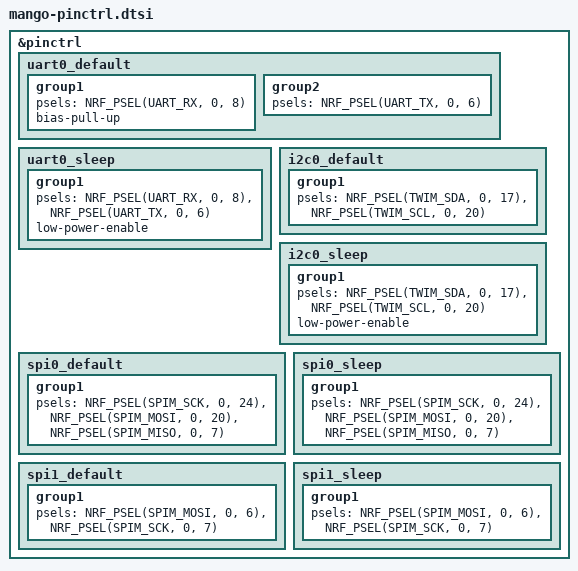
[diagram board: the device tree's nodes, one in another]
&pinctrl {
        uart0_default: uart0_default {
                group1 {
                        psels = <NRF_PSEL(UART_RX, 0, 8)>;
                        bias-pull-up;
                };
                group2 {
                        psels = <NRF_PSEL(UART_TX, 0, 6)>;
                };
        };

        uart0_sleep: uart0_sleep {
                group1 {
                        psels = <NRF_PSEL(UART_RX, 0, 8)>,
                                <NRF_PSEL(UART_TX, 0, 6)>;
                        low-power-enable;
                };
        };

        i2c0_default: i2c0_default {
                group1 {
                        psels = <NRF_PSEL(TWIM_SDA, 0, 17)>,
                                <NRF_PSEL(TWIM_SCL, 0, 20)>;
                };
        };

        i2c0_sleep: i2c0_sleep {
                group1 {
                        psels = <NRF_PSEL(TWIM_SDA, 0, 17)>,
                                <NRF_PSEL(TWIM_SCL, 0, 20)>;
                        low-power-enable;
                };
        };

        spi0_default: spi0_default {
                group1 {
                        psels = <NRF_PSEL(SPIM_SCK, 0, 24)>,
                                <NRF_PSEL(SPIM_MOSI, 0, 20)>,
                                // Unused pin, needed for SPI definition, but not used by the display driver itself.
                                <NRF_PSEL(SPIM_MISO, 0, 7)>; // 0.07 is not broken out on the n!n
                };
        };

        spi0_sleep: spi0_sleep {
                group1 {
                        psels = <NRF_PSEL(SPIM_SCK, 0, 24)>,
                                <NRF_PSEL(SPIM_MOSI, 0, 20)>,
                                // Unused pin, needed for SPI definition, but not used by the display driver itself.
                                <NRF_PSEL(SPIM_MISO, 0, 7)>; // 0.07 is not broken out on the n!n
                };
        };

        // The ws2812 driver only uses MOSI, but the SPIM still needs an SCK pin or the
        // LEDs stay dark. SCK used to be 0.24, which is also the display's SCK on spi0,
        // so LED updates clocked into the display. 0.07 is not broken out on the n!n.
        spi1_default: spi1_default {
                group1 {
                        psels = <NRF_PSEL(SPIM_MOSI, 0, 6)>,
                                <NRF_PSEL(SPIM_SCK, 0, 7)>;
                };
        };

        spi1_sleep: spi1_sleep {
                group1 {
                        psels = <NRF_PSEL(SPIM_MOSI, 0, 6)>,
                                <NRF_PSEL(SPIM_SCK, 0, 7)>;
                };
        };
};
